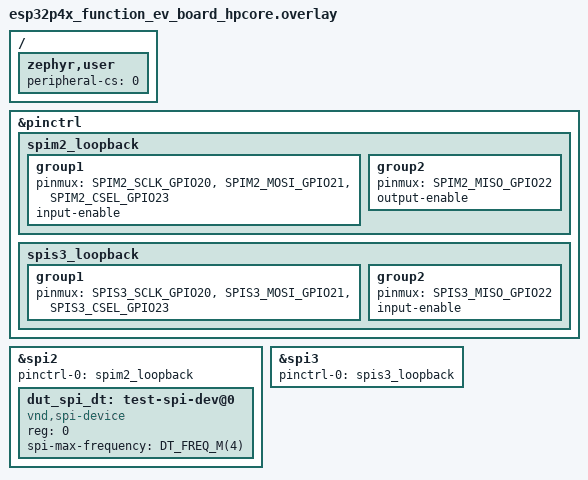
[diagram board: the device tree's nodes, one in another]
/*
 * Copyright (c) 2026 Espressif Systems (Shanghai) Co., Ltd.
 *
 * SPDX-License-Identifier: Apache-2.0
 *
 * SPI controller/target loopback on a single ESP32-P4 via the GPIO matrix.
 *   line  shared GPIO  spi2 controller   spi3 target
 *   SCLK  GPIO20       SPIM2_SCLK (out)  SPIS3_SCLK (in)
 *   MOSI  GPIO21       SPIM2_MOSI (out)  SPIS3_MOSI (in)
 *   MISO  GPIO22       SPIM2_MISO (in)   SPIS3_MISO (out)
 *   CS    GPIO23       SPIM2_CSEL (out)  SPIS3_CSEL (in)
 */

#include <dt-bindings/pinctrl/esp32p4-pinctrl.h>

/ {
	zephyr,user {
		peripheral-cs = <0>;
	};
};

&pinctrl {
	spim2_loopback: spim2_loopback {
		group1 {
			pinmux = <SPIM2_SCLK_GPIO20>,
				 <SPIM2_MOSI_GPIO21>,
				 <SPIM2_CSEL_GPIO23>;
			input-enable; /* preserve controller pad sense for loopback test */
		};

		group2 {
			pinmux = <SPIM2_MISO_GPIO22>;
			output-enable; /* preserve controller pad drive for loopback test */
		};
	};

	spis3_loopback: spis3_loopback {
		group1 {
			pinmux = <SPIS3_SCLK_GPIO20>,
				 <SPIS3_MOSI_GPIO21>,
				 <SPIS3_CSEL_GPIO23>;
		};

		group2 {
			pinmux = <SPIS3_MISO_GPIO22>;
			input-enable; /* preserve controller pad sense for loopback test */
		};
	};
};

&spi2 {
	#address-cells = <1>;
	#size-cells = <0>;
	status = "okay";
	pinctrl-0 = <&spim2_loopback>;
	pinctrl-names = "default";

	dut_spi_dt: test-spi-dev@0 {
		compatible = "vnd,spi-device";
		reg = <0>;
		spi-max-frequency = <DT_FREQ_M(4)>;
	};
};

dut_spis: &spi3 {
	#address-cells = <1>;
	#size-cells = <0>;
	status = "okay";
	pinctrl-0 = <&spis3_loopback>;
	pinctrl-names = "default";
};
